VERSION ""

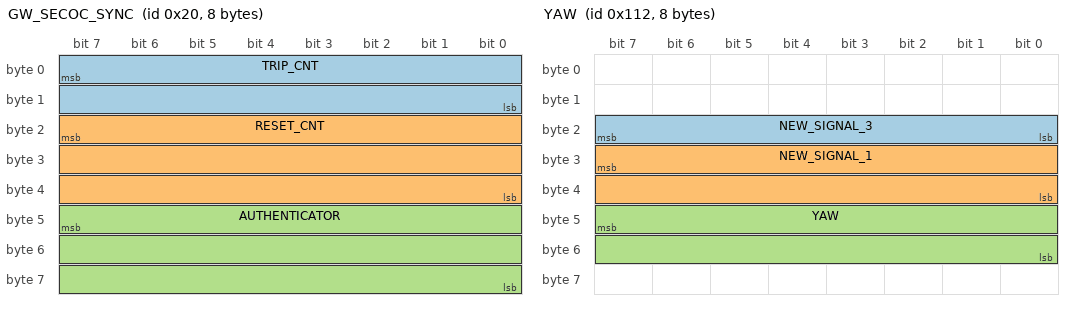
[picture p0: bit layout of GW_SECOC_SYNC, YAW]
BO_ 32 GW_SECOC_SYNC: 8 XXX
 SG_ TRIP_CNT : 7|16@0+ (1,0) [0|65535] "" XXX
 SG_ RESET_CNT : 23|24@0+ (1,0) [0|16777215] "" XXX
 SG_ AUTHENTICATOR : 47|24@0+ (1,0) [0|16777215] "" XXX

BO_ 89 NEW_MSG_59: 8 XXX
 SG_ NEW_SIGNAL_1 : 7|8@0+ (1,0) [0|255] "" XXX
 SG_ NEW_SIGNAL_2 : 11|4@0+ (1,0) [0|15] "" XXX

BO_ 237 NEW_MSG_ED: 8 XXX
 SG_ SECOC_CHECKSUM : 7|8@0+ (1,0) [0|255] "" XXX
 SG_ SECOC_COUNTER : 11|4@0+ (1,0) [0|15] "" XXX

BO_ 258 NEW_MSG_102: 8 XXX
 SG_ NEW_SIGNAL_1 : 23|16@0+ (1,0) [0|65535] "" XXX
 SG_ NEW_SIGNAL_2 : 39|16@0+ (1,0) [0|65535] "" XXX
 SG_ NEW_SIGNAL_3 : 55|16@0+ (1,0) [0|65535] "" XXX

BO_ 274 YAW: 8 XXX
 SG_ NEW_SIGNAL_3 : 23|8@0+ (1,0) [0|255] "" XXX
 SG_ NEW_SIGNAL_1 : 31|16@0+ (1,0) [0|255] "" XXX
 SG_ YAW : 47|16@0+ (1,0) [0|4095] "" XXX

BO_ 275 NEW_MSG_113: 8 XXX
 SG_ NEW_SIGNAL_2 : 16|1@0+ (1,0) [0|255] "" XXX
 SG_ NEW_SIGNAL_1 : 27|12@0+ (1,0) [0|255] "" XXX

BO_ 276 NEW_MSG_114: 8 XXX
 SG_ SECOC_CHECKSUM : 7|8@0+ (1,0) [0|255] "" XXX
 SG_ SECOC_COUNTER : 11|4@0+ (1,0) [0|15] "" XXX
 SG_ NEW_SIGNAL_1 : 23|24@0+ (1,0) [0|16777215] "" XXX

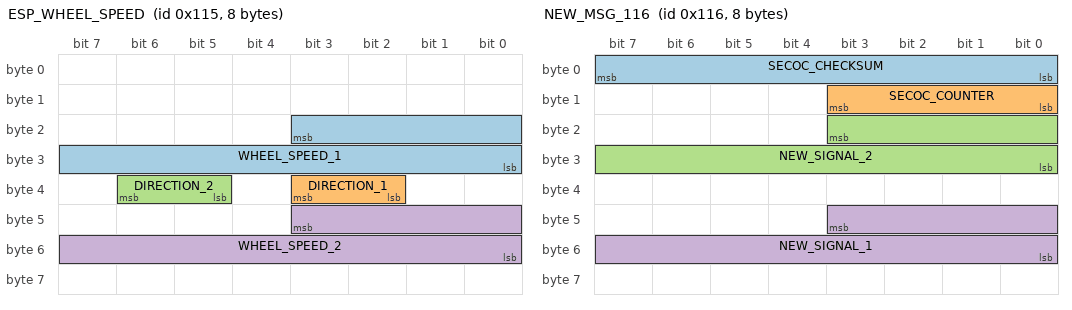
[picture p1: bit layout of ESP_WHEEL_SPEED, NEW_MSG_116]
BO_ 277 ESP_WHEEL_SPEED: 8 XXX
 SG_ WHEEL_SPEED_1 : 19|12@0+ (0.075,0) [0|255] "km/h" XXX
 SG_ DIRECTION_1 : 35|2@0+ (1,0) [0|3] "" XXX
 SG_ DIRECTION_2 : 38|2@0+ (1,0) [0|3] "" XXX
 SG_ WHEEL_SPEED_2 : 43|12@0+ (0.075,0) [0|255] "km/h" XXX

BO_ 278 NEW_MSG_116: 8 XXX
 SG_ SECOC_CHECKSUM : 7|8@0+ (1,0) [0|255] "" XXX
 SG_ SECOC_COUNTER : 11|4@0+ (1,0) [0|15] "" XXX
 SG_ NEW_SIGNAL_2 : 19|12@0+ (1,0) [0|4095] "" XXX
 SG_ NEW_SIGNAL_1 : 43|12@0+ (1,0) [0|4095] "" XXX

BO_ 280 NEW_MSG_118: 8 XXX
 SG_ NEW_SIGNAL_2 : 23|8@0+ (1,0) [0|255] "" XXX
 SG_ NEW_SIGNAL_1 : 63|8@0+ (1,0) [0|255] "" XXX

BO_ 281 NEW_MSG_119: 8 XXX
 SG_ NEW_SIGNAL_1 : 23|8@0+ (1,0) [0|255] "" XXX

BO_ 288 BRAKE_PEDAL: 8 XXX
 SG_ BRAKE_PEDAL_POS : 22|11@0+ (1,0) [0|127] "" XXX
 SG_ BRAKE_PEDAL_POS_INV : 54|15@0+ (1,0) [0|127] "" XXX

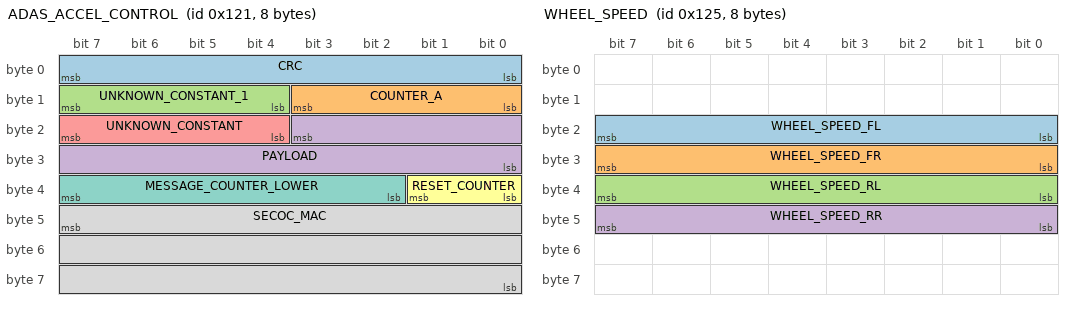
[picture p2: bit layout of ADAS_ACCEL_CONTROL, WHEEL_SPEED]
BO_ 289 ADAS_ACCEL_CONTROL: 8 XXX
 SG_ CRC : 7|8@0+ (1,0) [0|255] "" XXX
 SG_ COUNTER_A : 11|4@0+ (1,0) [0|255] "" XXX
 SG_ UNKNOWN_CONSTANT_1 : 15|4@0+ (1,0) [0|15] "" XXX
 SG_ PAYLOAD : 19|12@0+ (1,0) [0|4095] "" XXX
 SG_ UNKNOWN_CONSTANT : 23|4@0+ (1,0) [0|15] "" XXX
 SG_ RESET_COUNTER : 33|2@0+ (1,0) [0|3] "" XXX
 SG_ MESSAGE_COUNTER_LOWER : 39|6@0+ (1,0) [0|63] "" XXX
 SG_ SECOC_MAC : 47|24@0+ (1,0) [0|16777215] "" XXX

BO_ 293 WHEEL_SPEED: 8 XXX
 SG_ WHEEL_SPEED_FL : 23|8@0+ (1,0) [0|255] "" XXX
 SG_ WHEEL_SPEED_FR : 31|8@0+ (1,0) [0|255] "" XXX
 SG_ WHEEL_SPEED_RL : 39|8@0+ (1,0) [0|255] "" XXX
 SG_ WHEEL_SPEED_RR : 47|8@0+ (1,0) [0|255] "" XXX

BO_ 298 NEW_MSG_12A: 8 XXX
 SG_ NEW_SIGNAL_1 : 39|12@0+ (1,0) [0|4095] "" XXX
 SG_ NEW_SIGNAL_2 : 55|12@0+ (1,0) [0|4095] "" XXX

BO_ 336 NEW_MSG_150: 8 XXX
 SG_ NEW_SIGNAL_2 : 39|16@0+ (1,0) [0|65535] "" XXX

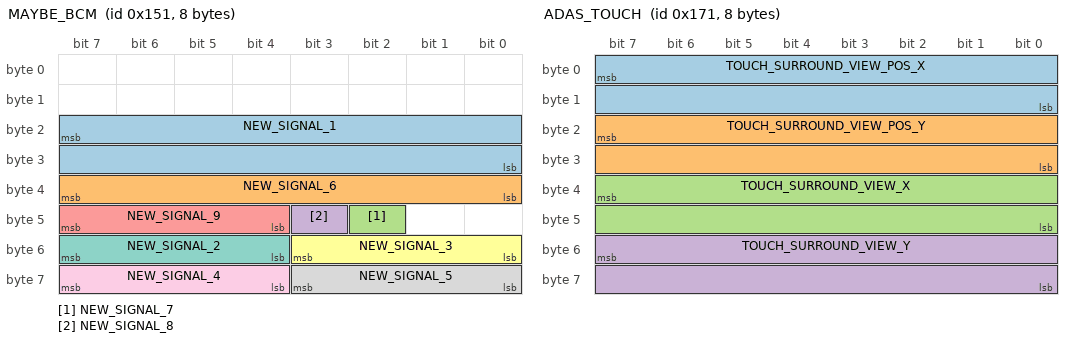
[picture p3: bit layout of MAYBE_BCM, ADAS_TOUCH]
BO_ 337 MAYBE_BCM: 8 XXX
 SG_ NEW_SIGNAL_1 : 23|16@0+ (1,0) [0|127] "" XXX
 SG_ NEW_SIGNAL_6 : 39|8@0+ (1,0) [0|255] "" XXX
 SG_ NEW_SIGNAL_7 : 42|1@0+ (1,0) [0|1] "" XXX
 SG_ NEW_SIGNAL_8 : 43|1@0+ (1,0) [0|1] "" XXX
 SG_ NEW_SIGNAL_9 : 47|4@0+ (1,0) [0|15] "" XXX
 SG_ NEW_SIGNAL_3 : 51|4@0+ (1,0) [0|15] "" XXX
 SG_ NEW_SIGNAL_2 : 55|4@0+ (1,0) [0|15] "" XXX
 SG_ NEW_SIGNAL_5 : 59|4@0+ (1,0) [0|15] "" XXX
 SG_ NEW_SIGNAL_4 : 63|4@0+ (1,0) [0|15] "" XXX

BO_ 345 NEW_MSG_159: 8 XXX
 SG_ NEW_SIGNAL_3 : 19|4@0+ (1,0) [0|15] "" XXX
 SG_ NEW_SIGNAL_1 : 23|4@0+ (1,0) [0|255] "" XXX
 SG_ NEW_SIGNAL_2 : 24|4@1+ (1,0) [0|15] "" XXX

BO_ 368 NEW_MSG_170: 8 XXX
 SG_ NEW_SIGNAL_3 : 23|8@0+ (1,0) [0|255] "" XXX
 SG_ NEW_SIGNAL_4 : 31|4@0+ (1,0) [0|15] "" XXX
 SG_ NEW_SIGNAL_1 : 39|12@0+ (1,0) [0|4095] "" XXX

BO_ 369 ADAS_TOUCH: 8 XXX
 SG_ TOUCH_SURROUND_VIEW_POS_X : 7|16@0+ (1,0) [0|65535] "" XXX
 SG_ TOUCH_SURROUND_VIEW_POS_Y : 23|16@0+ (1,0) [0|65535] "" XXX
 SG_ TOUCH_SURROUND_VIEW_X : 39|16@0+ (1,0) [0|65535] "" XXX
 SG_ TOUCH_SURROUND_VIEW_Y : 55|16@0+ (1,0) [0|65535] "" XXX

BO_ 372 NEW_MSG_174: 8 XXX
 SG_ NEW_SIGNAL_2 : 23|8@0+ (1,0) [0|255] "" XXX
 SG_ NEW_SIGNAL_1 : 31|8@0+ (1,0) [0|255] "" XXX
 SG_ NEW_SIGNAL_4 : 39|16@0+ (1,0) [0|255] "" XXX
 SG_ NEW_SIGNAL_5 : 55|8@0+ (1,0) [0|255] "" XXX
 SG_ NEW_SIGNAL_6 : 63|8@0+ (1,0) [0|255] "" XXX

BO_ 373 NEW_MSG_175: 8 XXX
 SG_ NEW_SIGNAL_1 : 23|16@0+ (1,0) [0|65535] "" XXX
 SG_ NEW_SIGNAL_2 : 39|16@0+ (1,0) [0|65535] "" XXX
 SG_ NEW_SIGNAL_3 : 55|16@0+ (1,0) [0|65535] "" XXX

BO_ 375 NEW_MSG_177: 8 XXX
 SG_ NEW_SIGNAL_2 : 39|16@0+ (1,0) [0|65535] "" XXX
 SG_ NEW_SIGNAL_1 : 55|16@0+ (1,0) [0|32767] "" XXX

BO_ 376 NEW_MSG_178: 8 XXX
 SG_ NEW_SIGNAL_1 : 23|16@0+ (1,0) [0|65535] "" XXX
 SG_ NEW_SIGNAL_2 : 47|8@0+ (1,0) [0|65535] "" XXX
 SG_ NEW_SIGNAL_3 : 55|16@0+ (1,0) [0|65535] "" XXX

BO_ 377 NEW_MSG_179: 8 XXX
 SG_ MAYBE_YAW_RELATED : 23|16@0+ (1,0) [0|255] "" XXX
 SG_ NEW_SIGNAL_2 : 39|16@0+ (1,0) [0|65535] "" XXX

BO_ 440 NEW_MSG_1B8: 8 XXX
 SG_ NEW_SIGNAL_1 : 51|12@0+ (1,0) [0|255] "" XXX

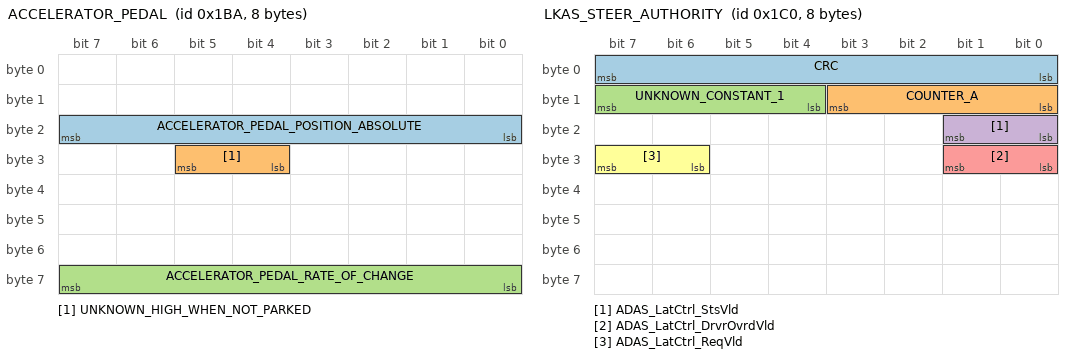
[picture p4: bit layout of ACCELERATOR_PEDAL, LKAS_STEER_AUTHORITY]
BO_ 442 ACCELERATOR_PEDAL: 8 XXX
 SG_ ACCELERATOR_PEDAL_POSITION_ABSOLUTE : 23|8@0+ (1,0) [0|255] "" XXX
 SG_ UNKNOWN_HIGH_WHEN_NOT_PARKED : 29|2@0+ (1,0) [0|3] "" XXX
 SG_ ACCELERATOR_PEDAL_RATE_OF_CHANGE : 63|8@0+ (1,0) [0|255] "" XXX

BO_ 448 LKAS_STEER_AUTHORITY: 8 XXX
 SG_ CRC : 7|8@0+ (1,0) [0|255] "" XXX
 SG_ COUNTER_A : 11|4@0+ (1,0) [0|15] "" XXX
 SG_ UNKNOWN_CONSTANT_1 : 15|4@0+ (1,0) [0|15] "" XXX
 SG_ ADAS_LatCtrl_StsVld : 17|2@0+ (1,0) [0|3] "" XXX
 SG_ ADAS_LatCtrl_DrvrOvrdVld : 25|2@0+ (1,0) [0|3] "" XXX
 SG_ ADAS_LatCtrl_ReqVld : 31|2@0+ (1,0) [0|3] "" XXX

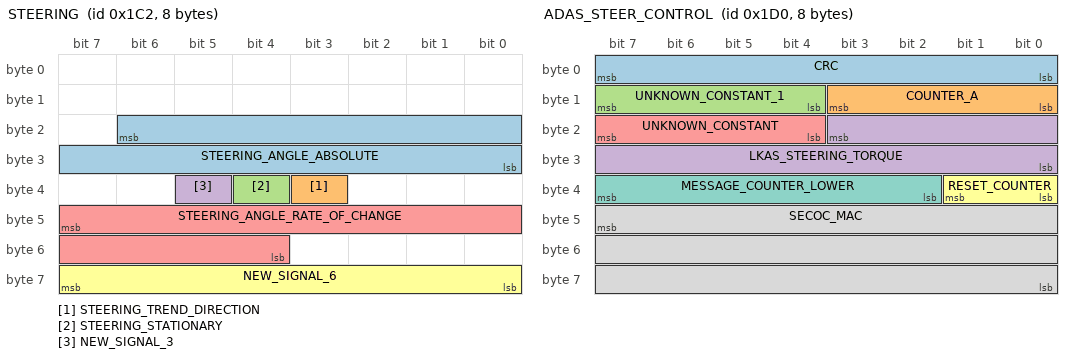
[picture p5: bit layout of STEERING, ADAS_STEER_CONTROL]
BO_ 450 STEERING: 8 XXX
 SG_ STEERING_ANGLE_ABSOLUTE : 22|15@0+ (0.0643,-800) [0|255] "" XXX
 SG_ STEERING_TREND_DIRECTION : 35|1@0+ (1,0) [0|1] "" XXX
 SG_ STEERING_STATIONARY : 36|1@0+ (1,0) [0|1] "" XXX
 SG_ NEW_SIGNAL_3 : 37|1@0+ (1,0) [0|255] "" XXX
 SG_ STEERING_ANGLE_RATE_OF_CHANGE : 47|12@0+ (1,0) [0|255] "" XXX
 SG_ NEW_SIGNAL_6 : 63|8@0+ (1,0) [0|255] "" XXX

BO_ 452 STEERING_WHEEL1: 8 XXX
 SG_ STEERING_WHEEL_INPUT_TORQUE : 23|12@0- (1,0) [-2048|2047] "" XXX
 SG_ STEERING_WHEEL_POS_ABSOLUTE : 55|16@0+ (1,-12500) [0|255] "" XXX

BO_ 464 ADAS_STEER_CONTROL: 8 XXX
 SG_ CRC : 7|8@0+ (1,0) [0|255] "" XXX
 SG_ COUNTER_A : 11|4@0+ (1,0) [0|15] "" XXX
 SG_ UNKNOWN_CONSTANT_1 : 15|4@0+ (1,0) [0|15] "" XXX
 SG_ LKAS_STEERING_TORQUE : 19|12@0+ (1,-192) [-192|192] "" XXX
 SG_ UNKNOWN_CONSTANT : 23|4@0+ (1,0) [0|15] "" XXX
 SG_ RESET_COUNTER : 33|2@0+ (1,0) [0|3] "" XXX
 SG_ MESSAGE_COUNTER_LOWER : 39|6@0+ (1,0) [0|3] "" XXX
 SG_ SECOC_MAC : 47|24@0+ (1,0) [0|16777215] "" XXX

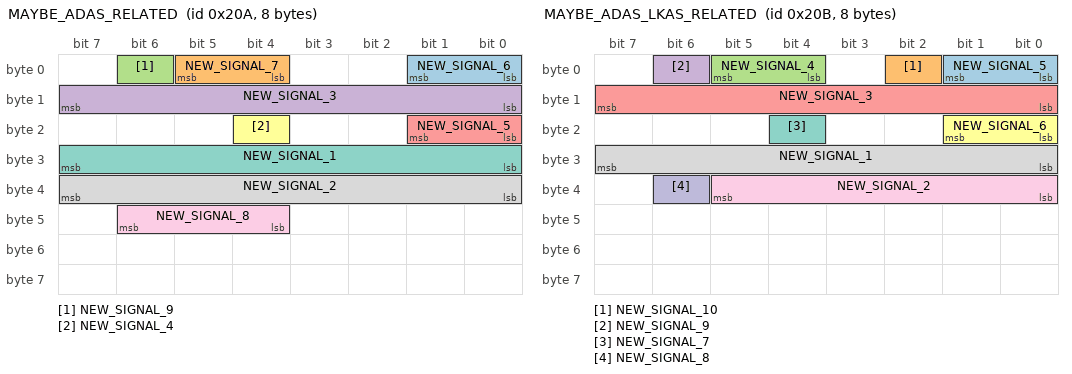
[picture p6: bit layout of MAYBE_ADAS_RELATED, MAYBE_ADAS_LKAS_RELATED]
BO_ 522 MAYBE_ADAS_RELATED: 8 XXX
 SG_ NEW_SIGNAL_6 : 1|2@0+ (1,0) [0|3] "" XXX
 SG_ NEW_SIGNAL_7 : 5|2@0+ (1,0) [0|7] "" XXX
 SG_ NEW_SIGNAL_9 : 6|1@0+ (1,0) [0|1] "" XXX
 SG_ NEW_SIGNAL_3 : 15|8@0+ (1,0) [0|255] "" XXX
 SG_ NEW_SIGNAL_5 : 17|2@0+ (1,0) [0|3] "" XXX
 SG_ NEW_SIGNAL_4 : 20|1@0+ (1,0) [0|1] "" XXX
 SG_ NEW_SIGNAL_1 : 31|8@0+ (1,0) [0|255] "" XXX
 SG_ NEW_SIGNAL_2 : 39|8@0+ (1,0) [0|255] "" XXX
 SG_ NEW_SIGNAL_8 : 46|3@0+ (1,0) [0|7] "" XXX

BO_ 523 MAYBE_ADAS_LKAS_RELATED: 8 XXX
 SG_ NEW_SIGNAL_5 : 1|2@0+ (1,0) [0|1] "" XXX
 SG_ NEW_SIGNAL_10 : 2|1@0+ (1,0) [0|1] "" XXX
 SG_ NEW_SIGNAL_4 : 5|2@0+ (1,0) [0|1] "" XXX
 SG_ NEW_SIGNAL_9 : 6|1@0+ (1,0) [0|1] "" XXX
 SG_ NEW_SIGNAL_3 : 15|8@0+ (1,0) [0|255] "" XXX
 SG_ NEW_SIGNAL_6 : 17|2@0+ (1,0) [0|3] "" XXX
 SG_ NEW_SIGNAL_7 : 20|1@0+ (1,0) [0|1] "" XXX
 SG_ NEW_SIGNAL_1 : 31|8@0+ (1,0) [0|255] "" XXX
 SG_ NEW_SIGNAL_2 : 37|6@0+ (1,0) [0|255] "" XXX
 SG_ NEW_SIGNAL_8 : 38|1@0+ (1,0) [0|1] "" XXX

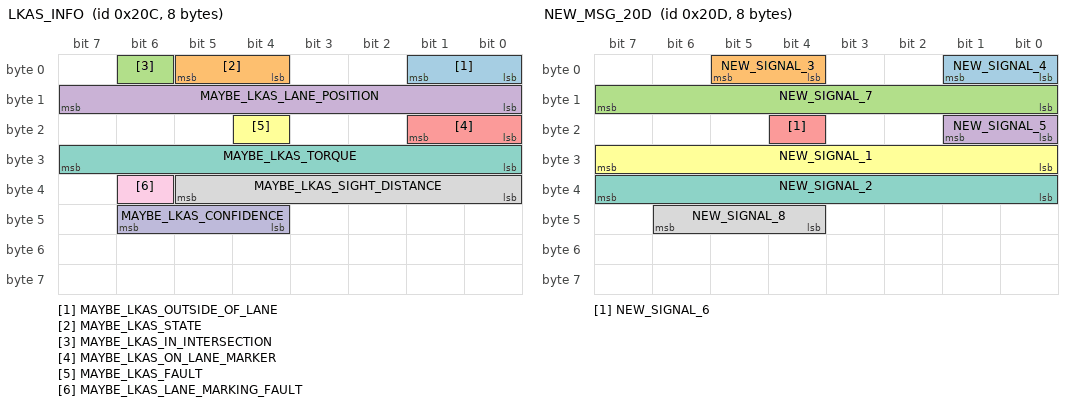
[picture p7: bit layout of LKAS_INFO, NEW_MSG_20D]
BO_ 524 LKAS_INFO: 8 XXX
 SG_ MAYBE_LKAS_OUTSIDE_OF_LANE : 1|2@0+ (1,0) [0|3] "" XXX
 SG_ MAYBE_LKAS_STATE : 5|2@0+ (1,0) [0|7] "" XXX
 SG_ MAYBE_LKAS_IN_INTERSECTION : 6|1@0+ (1,0) [0|1] "" XXX
 SG_ MAYBE_LKAS_LANE_POSITION : 15|8@0+ (1,0) [0|255] "" XXX
 SG_ MAYBE_LKAS_ON_LANE_MARKER : 17|2@0+ (1,0) [0|3] "" XXX
 SG_ MAYBE_LKAS_FAULT : 20|1@0+ (1,0) [0|1] "" XXX
 SG_ MAYBE_LKAS_TORQUE : 31|8@0+ (1,0) [0|255] "" XXX
 SG_ MAYBE_LKAS_SIGHT_DISTANCE : 37|6@0+ (1,0) [0|255] "" XXX
 SG_ MAYBE_LKAS_LANE_MARKING_FAULT : 38|1@0+ (1,0) [0|1] "" XXX
 SG_ MAYBE_LKAS_CONFIDENCE : 46|3@0+ (1,0) [0|7] "" XXX

BO_ 525 NEW_MSG_20D: 8 XXX
 SG_ NEW_SIGNAL_4 : 1|2@0+ (1,0) [0|3] "" XXX
 SG_ NEW_SIGNAL_3 : 5|2@0+ (1,0) [0|3] "" XXX
 SG_ NEW_SIGNAL_7 : 15|8@0+ (1,0) [0|255] "" XXX
 SG_ NEW_SIGNAL_5 : 17|2@0+ (1,0) [0|3] "" XXX
 SG_ NEW_SIGNAL_6 : 20|1@0+ (1,0) [0|1] "" XXX
 SG_ NEW_SIGNAL_1 : 31|8@0+ (1,0) [0|127] "" XXX
 SG_ NEW_SIGNAL_2 : 39|8@0+ (1,0) [0|255] "" XXX
 SG_ NEW_SIGNAL_8 : 46|3@0+ (1,0) [0|7] "" XXX

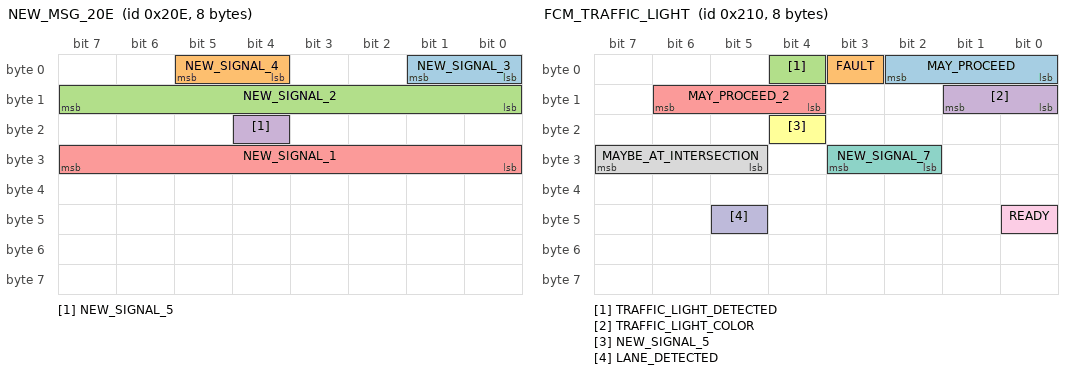
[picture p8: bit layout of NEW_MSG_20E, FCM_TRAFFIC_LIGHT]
BO_ 526 NEW_MSG_20E: 8 XXX
 SG_ NEW_SIGNAL_3 : 1|2@0+ (1,0) [0|3] "" XXX
 SG_ NEW_SIGNAL_4 : 5|2@0+ (1,0) [0|3] "" XXX
 SG_ NEW_SIGNAL_2 : 15|8@0+ (1,0) [0|255] "" XXX
 SG_ NEW_SIGNAL_5 : 20|1@0+ (1,0) [0|1] "" XXX
 SG_ NEW_SIGNAL_1 : 31|8@0+ (1,0) [0|255] "" XXX

BO_ 527 NEW_MSG_20F: 8 XXX
 SG_ NEW_SIGNAL_2 : 2|3@0+ (1,0) [0|7] "" XXX
 SG_ NEW_SIGNAL_1 : 5|3@0+ (1,0) [0|7] "" XXX

BO_ 528 FCM_TRAFFIC_LIGHT: 8 XXX
 SG_ MAY_PROCEED : 2|3@0+ (1,0) [0|7] "" XXX
 SG_ FAULT : 3|1@0+ (1,0) [0|1] "" XXX
 SG_ TRAFFIC_LIGHT_DETECTED : 4|1@0+ (1,0) [0|1] "" XXX
 SG_ TRAFFIC_LIGHT_COLOR : 9|2@0+ (1,0) [0|3] "" XXX
 SG_ MAY_PROCEED_2 : 14|3@0+ (1,0) [0|7] "" XXX
 SG_ NEW_SIGNAL_5 : 20|1@0+ (1,0) [0|1] "" XXX
 SG_ NEW_SIGNAL_7 : 27|2@0+ (1,0) [0|3] "" XXX
 SG_ MAYBE_AT_INTERSECTION : 31|3@0+ (1,0) [0|7] "" XXX
 SG_ READY : 40|1@0+ (1,0) [0|1] "" XXX
 SG_ LANE_DETECTED : 45|1@0+ (1,0) [0|1] "" XXX

BO_ 532 BCM: 16 XXX
 SG_ NEW_SIGNAL_6 : 12|1@0+ (1,0) [0|1] "" XXX
 SG_ BRAKE_PRESSED_1 : 14|1@0+ (1,0) [0|1] "" XXX
 SG_ DRIVE_MODE_1 : 18|3@0+ (1,0) [0|7] "" XXX
 SG_ DRIVE_MODE_2 : 26|3@0+ (1,0) [0|7] "" XXX
 SG_ NEW_SIGNAL_4 : 43|4@0+ (1,0) [0|7] "" XXX
 SG_ ACCELERATOR_PEDAL_POSITION_ABSOLUTE : 55|8@0+ (1,0) [0|255] "" XXX
 SG_ BRAKE_PRESSED_2 : 56|1@0+ (1,0) [0|1] "" XXX
 SG_ NEW_SIGNAL_1 : 60|2@0+ (1,0) [0|3] "" XXX

BO_ 588 NEW_MSG_24C: 32 XXX
 SG_ NEW_SIGNAL_7 : 23|8@0+ (1,0) [0|255] "" XXX
 SG_ NEW_SIGNAL_4 : 31|16@0+ (1,0) [0|65535] "" XXX
 SG_ NEW_SIGNAL_5 : 43|12@0+ (1,0) [0|255] "" XXX
 SG_ NEW_SIGNAL_3 : 59|12@0+ (1,0) [0|255] "" XXX
 SG_ NEW_SIGNAL_2 : 79|8@0+ (1,0) [0|255] "" XXX
 SG_ NEW_SIGNAL_1 : 111|8@0+ (1,0) [0|255] "" XXX
 SG_ NEW_SIGNAL_6 : 143|19@0+ (1,0) [0|524287] "" XXX
 SG_ NEW_SIGNAL_8 : 156|3@0+ (1,0) [0|7] "" XXX
 SG_ NEW_SIGNAL_9 : 172|5@0+ (1,0) [0|31] "" XXX
 SG_ NEW_SIGNAL_10 : 191|8@0+ (1,0) [0|255] "" XXX
 SG_ NEW_SIGNAL_11 : 218|3@0+ (1,0) [0|7] "" XXX

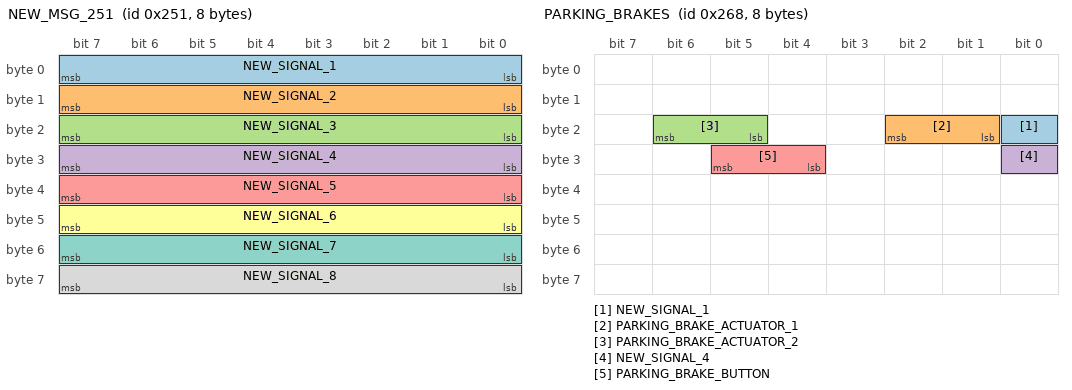
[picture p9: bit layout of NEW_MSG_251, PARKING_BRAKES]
BO_ 593 NEW_MSG_251: 8 XXX
 SG_ NEW_SIGNAL_1 : 7|8@0+ (1,0) [0|255] "" XXX
 SG_ NEW_SIGNAL_2 : 8|8@1+ (1,0) [0|255] "" XXX
 SG_ NEW_SIGNAL_3 : 23|8@0+ (1,0) [0|255] "" XXX
 SG_ NEW_SIGNAL_4 : 31|8@0+ (1,0) [0|255] "" XXX
 SG_ NEW_SIGNAL_5 : 39|8@0+ (1,0) [0|255] "" XXX
 SG_ NEW_SIGNAL_6 : 47|8@0+ (1,0) [0|255] "" XXX
 SG_ NEW_SIGNAL_7 : 55|8@0+ (1,0) [0|255] "" XXX
 SG_ NEW_SIGNAL_8 : 63|8@0+ (1,0) [0|255] "" XXX

BO_ 616 PARKING_BRAKES: 8 XXX
 SG_ NEW_SIGNAL_1 : 16|1@0+ (1,0) [0|1] "" XXX
 SG_ PARKING_BRAKE_ACTUATOR_1 : 18|2@0+ (1,0) [0|3] "" XXX
 SG_ PARKING_BRAKE_ACTUATOR_2 : 22|2@0+ (1,0) [0|3] "" XXX
 SG_ NEW_SIGNAL_4 : 24|1@0+ (1,0) [0|1] "" XXX
 SG_ PARKING_BRAKE_BUTTON : 29|2@0+ (1,0) [0|3] "" XXX

BO_ 678 NEW_MSG_2A6: 8 XXX
 SG_ NEW_SIGNAL_1 : 11|4@0+ (1,0) [0|15] "" XXX
 SG_ NEW_SIGNAL_2 : 18|3@0+ (1,0) [0|7] "" XXX

BO_ 767 NEW_MSG_2FF: 8 XXX
 SG_ NEW_SIGNAL_1 : 23|16@0+ (1,0) [0|255] "" XXX
 SG_ NEW_SIGNAL_2 : 39|16@0+ (1,0) [0|65535] "" XXX

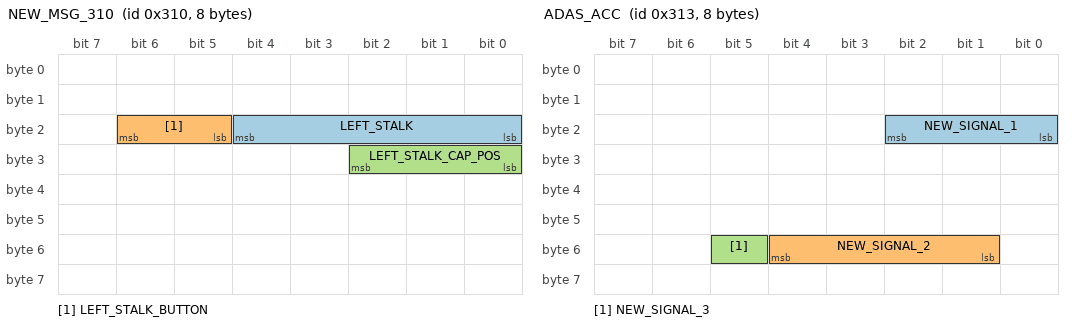
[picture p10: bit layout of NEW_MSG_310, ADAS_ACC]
BO_ 784 NEW_MSG_310: 8 XXX
 SG_ LEFT_STALK : 20|5@0+ (1,0) [0|31] "" XXX
 SG_ LEFT_STALK_BUTTON : 22|2@0+ (1,0) [0|1] "" XXX
 SG_ LEFT_STALK_CAP_POS : 26|3@0+ (1,0) [0|1] "" XXX

BO_ 785 NEW_MSG_311: 8 XXX
 SG_ NEW_SIGNAL_1 : 52|4@0+ (1,0) [0|15] "" XXX

BO_ 787 ADAS_ACC: 8 XXX
 SG_ NEW_SIGNAL_1 : 18|3@0+ (1,0) [0|7] "" XXX
 SG_ NEW_SIGNAL_2 : 52|4@0+ (1,0) [0|1] "" XXX
 SG_ NEW_SIGNAL_3 : 53|1@0+ (1,0) [0|1] "" XXX

BO_ 788 NEW_MSG_314: 8 XXX
 SG_ NEW_SIGNAL_2 : 23|8@0+ (1,0) [0|255] "" XXX
 SG_ NEW_SIGNAL_3 : 31|8@0+ (1,0) [0|255] "" XXX
 SG_ NEW_SIGNAL_4 : 39|8@0+ (1,0) [0|255] "" XXX
 SG_ NEW_SIGNAL_5 : 47|8@0+ (1,0) [0|255] "" XXX
 SG_ NEW_SIGNAL_1 : 55|8@0+ (1,0) [0|255] "" XXX
 SG_ NEW_SIGNAL_6 : 63|8@0+ (1,0) [0|255] "" XXX

BO_ 789 NEW_MSG_315: 8 XXX
 SG_ NEW_SIGNAL_1 : 43|1@0+ (1,0) [0|1] "" XXX

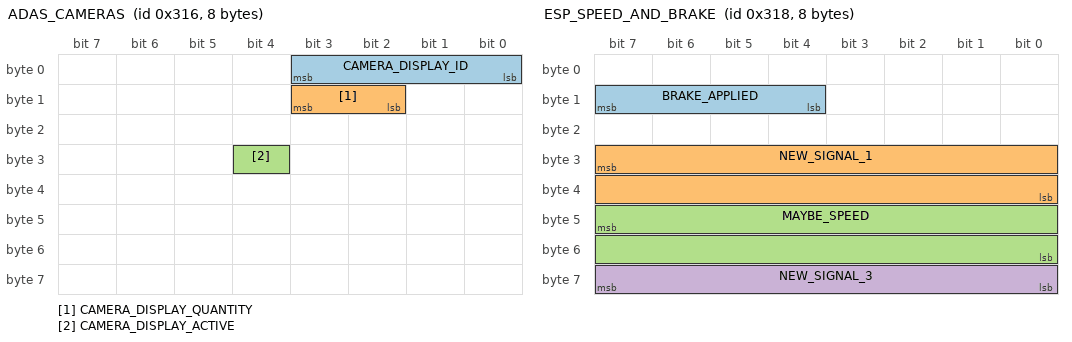
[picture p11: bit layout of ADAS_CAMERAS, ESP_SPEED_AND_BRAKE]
BO_ 790 ADAS_CAMERAS: 8 XXX
 SG_ CAMERA_DISPLAY_ID : 3|4@0+ (1,0) [0|15] "" XXX
 SG_ CAMERA_DISPLAY_QUANTITY : 11|2@0+ (1,0) [0|3] "" XXX
 SG_ CAMERA_DISPLAY_ACTIVE : 28|1@0+ (1,0) [0|1] "" XXX

BO_ 791 NEW_MSG_317: 8 XXX
 SG_ NEW_SIGNAL_1 : 23|8@0+ (1,0) [0|3] "" XXX
 SG_ NEW_SIGNAL_3 : 31|8@0+ (1,0) [0|255] "" XXX
 SG_ NEW_SIGNAL_4 : 39|8@0+ (1,0) [0|255] "" XXX
 SG_ NEW_SIGNAL_5 : 47|8@0+ (1,0) [0|255] "" XXX
 SG_ NEW_SIGNAL_2 : 55|8@0+ (1,0) [0|255] "" XXX

BO_ 792 ESP_SPEED_AND_BRAKE: 8 XXX
 SG_ BRAKE_APPLIED : 15|4@0+ (1,0) [0|15] "" XXX
 SG_ NEW_SIGNAL_1 : 31|16@0+ (1,0) [0|255] "" XXX
 SG_ MAYBE_SPEED : 47|16@0+ (1,0) [0|255] "" XXX
 SG_ NEW_SIGNAL_3 : 63|8@0+ (1,0) [0|255] "" XXX

BO_ 794 NEW_MSG_31A: 8 XXX
 SG_ NEW_SIGNAL_1 : 23|8@0+ (1,0) [0|255] "" XXX
 SG_ NEW_SIGNAL_2 : 63|8@0+ (1,0) [0|255] "" XXX

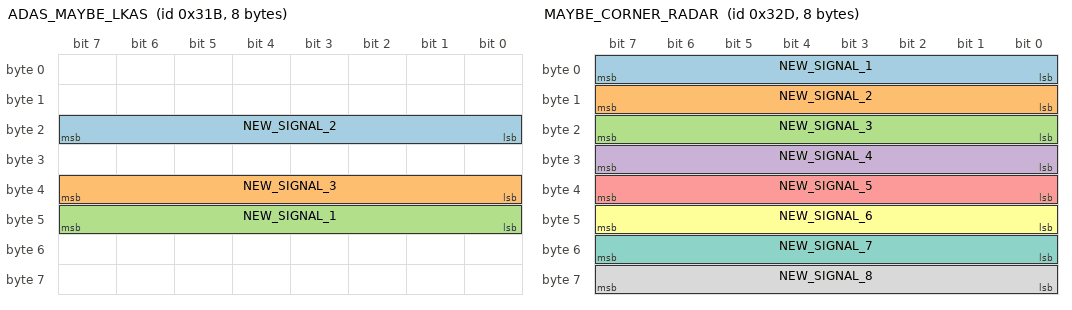
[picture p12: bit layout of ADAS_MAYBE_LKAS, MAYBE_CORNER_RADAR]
BO_ 795 ADAS_MAYBE_LKAS: 8 XXX
 SG_ NEW_SIGNAL_2 : 23|8@0+ (1,0) [0|255] "" XXX
 SG_ NEW_SIGNAL_3 : 39|8@0+ (1,0) [0|255] "" XXX
 SG_ NEW_SIGNAL_1 : 40|8@1+ (1,0) [0|255] "" XXX

BO_ 796 ADAS_ACC_HUD: 8 XXX

BO_ 801 NEW_MSG_321: 8 XXX
 SG_ NEW_SIGNAL_1 : 49|2@0+ (1,0) [0|3] "" XXX

BO_ 813 MAYBE_CORNER_RADAR: 8 XXX
 SG_ NEW_SIGNAL_1 : 7|8@0+ (1,0) [0|255] "" XXX
 SG_ NEW_SIGNAL_2 : 15|8@0+ (1,0) [0|255] "" XXX
 SG_ NEW_SIGNAL_3 : 23|8@0+ (1,0) [0|255] "" XXX
 SG_ NEW_SIGNAL_4 : 31|8@0+ (1,0) [0|255] "" XXX
 SG_ NEW_SIGNAL_5 : 39|8@0+ (1,0) [0|255] "" XXX
 SG_ NEW_SIGNAL_6 : 47|8@0+ (1,0) [0|255] "" XXX
 SG_ NEW_SIGNAL_7 : 55|8@0+ (1,0) [0|255] "" XXX
 SG_ NEW_SIGNAL_8 : 63|8@0+ (1,0) [0|255] "" XXX

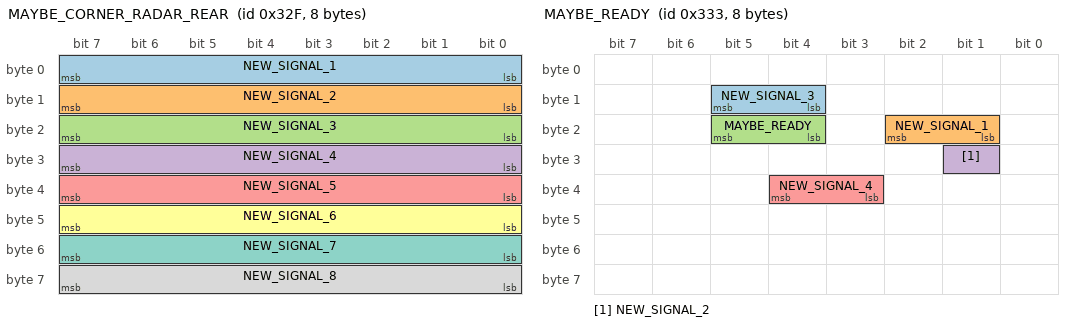
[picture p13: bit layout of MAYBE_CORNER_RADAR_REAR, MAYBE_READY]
BO_ 815 MAYBE_CORNER_RADAR_REAR: 8 XXX
 SG_ NEW_SIGNAL_1 : 7|8@0+ (1,0) [0|255] "" XXX
 SG_ NEW_SIGNAL_2 : 15|8@0+ (1,0) [0|255] "" XXX
 SG_ NEW_SIGNAL_3 : 23|8@0+ (1,0) [0|255] "" XXX
 SG_ NEW_SIGNAL_4 : 31|8@0+ (1,0) [0|255] "" XXX
 SG_ NEW_SIGNAL_5 : 39|8@0+ (1,0) [0|255] "" XXX
 SG_ NEW_SIGNAL_6 : 47|8@0+ (1,0) [0|255] "" XXX
 SG_ NEW_SIGNAL_7 : 55|8@0+ (1,0) [0|255] "" XXX
 SG_ NEW_SIGNAL_8 : 63|8@0+ (1,0) [0|255] "" XXX

BO_ 817 NEW_MSG_331: 16 XXX
 SG_ NEW_SIGNAL_1 : 20|2@0+ (1,0) [0|3] "" XXX

BO_ 819 MAYBE_READY: 8 XXX
 SG_ NEW_SIGNAL_3 : 13|2@0+ (1,0) [0|3] "" XXX
 SG_ NEW_SIGNAL_1 : 18|2@0+ (1,0) [0|3] "" XXX
 SG_ MAYBE_READY : 21|2@0+ (1,0) [0|3] "" XXX
 SG_ NEW_SIGNAL_2 : 25|1@0+ (1,0) [0|1] "" XXX
 SG_ NEW_SIGNAL_4 : 36|2@0+ (1,0) [0|3] "" XXX

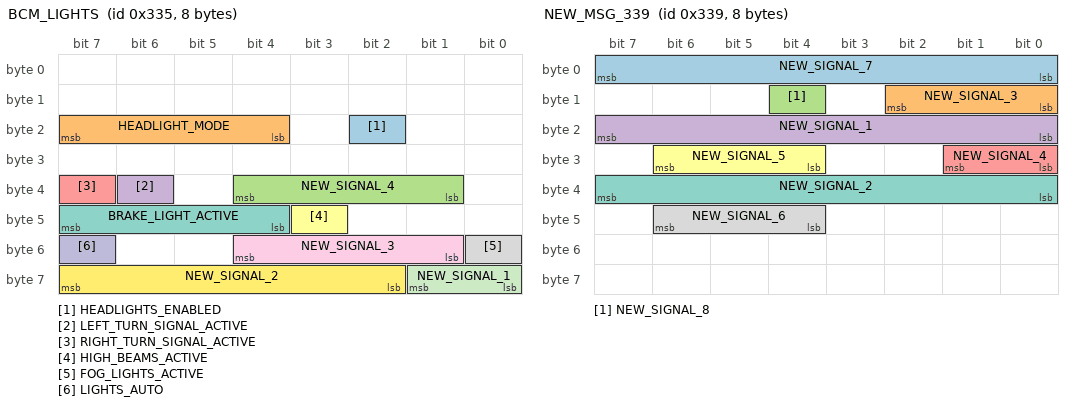
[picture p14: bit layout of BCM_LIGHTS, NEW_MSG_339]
BO_ 821 BCM_LIGHTS: 8 XXX
 SG_ HEADLIGHTS_ENABLED : 18|1@0+ (1,0) [0|1] "" XXX
 SG_ HEADLIGHT_MODE : 23|4@0+ (1,0) [0|255] "" XXX
 SG_ NEW_SIGNAL_4 : 36|4@0+ (1,0) [0|15] "" XXX
 SG_ LEFT_TURN_SIGNAL_ACTIVE : 38|1@0+ (1,0) [0|1] "" XXX
 SG_ RIGHT_TURN_SIGNAL_ACTIVE : 39|1@0+ (1,0) [0|1] "" XXX
 SG_ HIGH_BEAMS_ACTIVE : 43|1@0+ (1,0) [0|1] "" XXX
 SG_ BRAKE_LIGHT_ACTIVE : 47|4@0+ (1,0) [0|15] "" XXX
 SG_ FOG_LIGHTS_ACTIVE : 48|1@0+ (1,0) [0|255] "" XXX
 SG_ NEW_SIGNAL_3 : 52|4@0+ (1,0) [0|15] "" XXX
 SG_ LIGHTS_AUTO : 55|1@0+ (1,0) [0|127] "" XXX
 SG_ NEW_SIGNAL_1 : 57|2@0+ (1,0) [0|3] "" XXX
 SG_ NEW_SIGNAL_2 : 63|6@0+ (1,0) [0|63] "" XXX

BO_ 825 NEW_MSG_339: 8 XXX
 SG_ NEW_SIGNAL_7 : 7|8@0+ (1,0) [0|255] "" XXX
 SG_ NEW_SIGNAL_3 : 10|3@0+ (1,0) [0|7] "" XXX
 SG_ NEW_SIGNAL_8 : 12|1@0+ (1,0) [0|1] "" XXX
 SG_ NEW_SIGNAL_1 : 23|8@0+ (1,0) [0|255] "" XXX
 SG_ NEW_SIGNAL_4 : 25|2@0+ (1,0) [0|3] "" XXX
 SG_ NEW_SIGNAL_5 : 30|3@0+ (1,0) [0|7] "" XXX
 SG_ NEW_SIGNAL_2 : 39|8@0+ (1,0) [0|255] "" XXX
 SG_ NEW_SIGNAL_6 : 46|3@0+ (1,0) [0|7] "" XXX

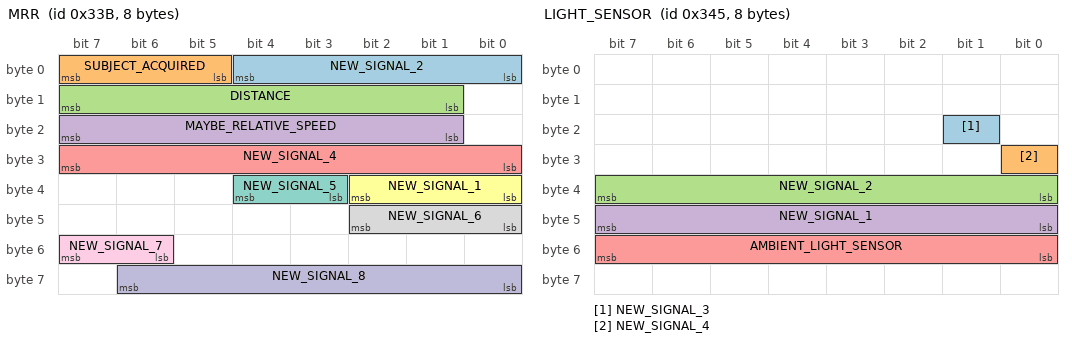
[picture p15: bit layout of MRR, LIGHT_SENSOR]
BO_ 827 MRR: 8 XXX
 SG_ NEW_SIGNAL_2 : 4|5@0+ (1,0) [0|31] "" XXX
 SG_ SUBJECT_ACQUIRED : 7|3@0+ (1,0) [0|1] "" XXX
 SG_ DISTANCE : 15|7@0+ (1,0) [0|255] "" XXX
 SG_ MAYBE_RELATIVE_SPEED : 23|7@0+ (1,0) [0|255] "" XXX
 SG_ NEW_SIGNAL_4 : 31|8@0+ (1,0) [0|255] "" XXX
 SG_ NEW_SIGNAL_1 : 34|3@0+ (1,0) [0|7] "" XXX
 SG_ NEW_SIGNAL_5 : 36|2@0+ (1,0) [0|255] "" XXX
 SG_ NEW_SIGNAL_6 : 42|3@0+ (1,0) [0|255] "" XXX
 SG_ NEW_SIGNAL_7 : 55|2@0+ (1,0) [0|255] "" XXX
 SG_ NEW_SIGNAL_8 : 62|7@0+ (1,0) [0|255] "" XXX

BO_ 835 BCM_DOORS: 8 XXX
 SG_ PARKED : 18|1@0+ (1,0) [0|1] "" XXX
 SG_ MAYBE_DOOR_OPEN : 22|2@0+ (1,0) [0|3] "" XXX

BO_ 837 LIGHT_SENSOR: 8 XXX
 SG_ NEW_SIGNAL_3 : 17|1@0+ (1,0) [0|1] "" XXX
 SG_ NEW_SIGNAL_4 : 24|1@0+ (1,0) [0|1] "" XXX
 SG_ NEW_SIGNAL_2 : 39|8@0+ (1,0) [0|255] "" XXX
 SG_ NEW_SIGNAL_1 : 47|8@0+ (1,0) [0|255] "" XXX
 SG_ AMBIENT_LIGHT_SENSOR : 55|8@0+ (1,0) [0|15] "" XXX

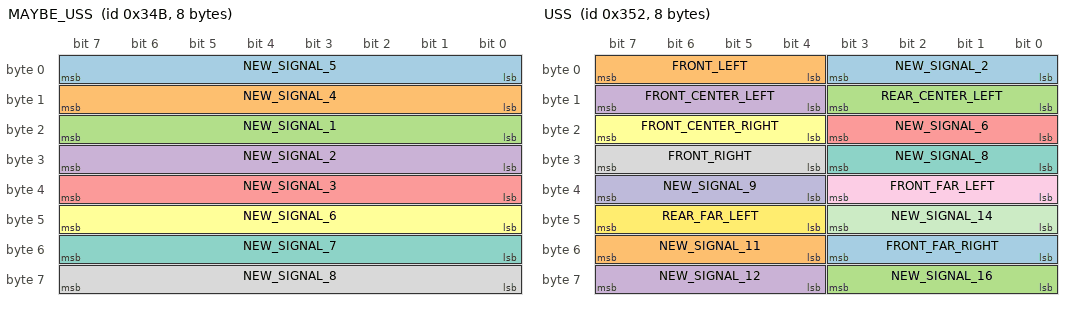
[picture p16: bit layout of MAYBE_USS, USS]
BO_ 843 MAYBE_USS: 8 XXX
 SG_ NEW_SIGNAL_5 : 7|8@0+ (1,0) [0|255] "" XXX
 SG_ NEW_SIGNAL_4 : 15|8@0+ (1,0) [0|255] "" XXX
 SG_ NEW_SIGNAL_1 : 23|8@0+ (1,0) [0|255] "" XXX
 SG_ NEW_SIGNAL_2 : 31|8@0+ (1,0) [0|255] "" XXX
 SG_ NEW_SIGNAL_3 : 39|8@0+ (1,0) [0|255] "" XXX
 SG_ NEW_SIGNAL_6 : 47|8@0+ (1,0) [0|255] "" XXX
 SG_ NEW_SIGNAL_7 : 55|8@0+ (1,0) [0|255] "" XXX
 SG_ NEW_SIGNAL_8 : 63|8@0+ (1,0) [0|255] "" XXX

BO_ 845 NEW_MSG_34D: 8 XXX
 SG_ NEW_SIGNAL_2 : 23|8@0+ (1,0) [0|255] "" XXX

BO_ 849 NEW_MSG_351: 8 XXX
 SG_ NEW_SIGNAL_1 : 48|8@1+ (1,0) [0|255] "" XXX

BO_ 850 USS: 8 XXX
 SG_ NEW_SIGNAL_2 : 3|4@0+ (1,0) [0|15] "" XXX
 SG_ FRONT_LEFT : 7|4@0+ (1,0) [0|15] "" XXX
 SG_ REAR_CENTER_LEFT : 11|4@0+ (1,0) [0|15] "" XXX
 SG_ FRONT_CENTER_LEFT : 15|4@0+ (1,0) [0|15] "" XXX
 SG_ NEW_SIGNAL_6 : 19|4@0+ (1,0) [0|15] "" XXX
 SG_ FRONT_CENTER_RIGHT : 23|4@0+ (1,0) [0|15] "" XXX
 SG_ NEW_SIGNAL_8 : 27|4@0+ (1,0) [0|15] "" XXX
 SG_ FRONT_RIGHT : 31|4@0+ (1,0) [0|15] "" XXX
 SG_ FRONT_FAR_LEFT : 35|4@0+ (1,0) [0|15] "" XXX
 SG_ NEW_SIGNAL_9 : 39|4@0+ (1,0) [0|15] "" XXX
 SG_ NEW_SIGNAL_14 : 43|4@0+ (1,0) [0|15] "" XXX
 SG_ REAR_FAR_LEFT : 47|4@0+ (1,0) [0|15] "" XXX
 SG_ FRONT_FAR_RIGHT : 51|4@0+ (1,0) [0|15] "" XXX
 SG_ NEW_SIGNAL_11 : 55|4@0+ (1,0) [0|15] "" XXX
 SG_ NEW_SIGNAL_16 : 59|4@0+ (1,0) [0|15] "" XXX
 SG_ NEW_SIGNAL_12 : 63|4@0+ (1,0) [0|15] "" XXX

BO_ 851 UNKNOWN_CHANGES_WITH_DRIVE_MODE_1: 8 XXX
 SG_ NEW_SIGNAL_1 : 23|4@0+ (1,0) [0|15] "" XXX

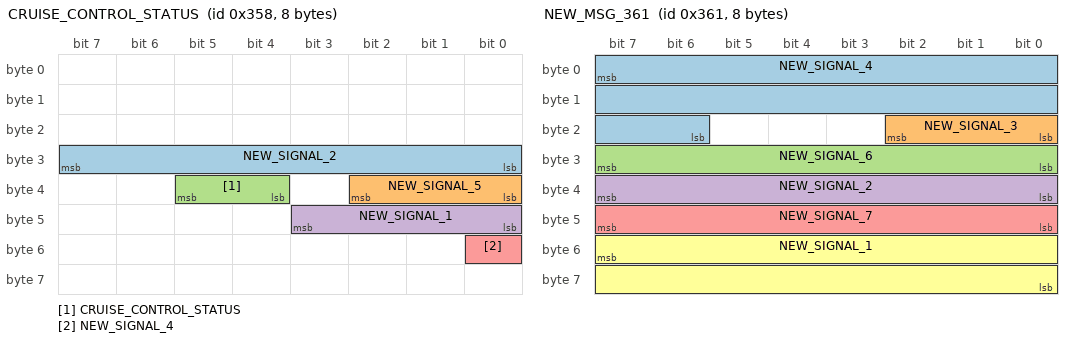
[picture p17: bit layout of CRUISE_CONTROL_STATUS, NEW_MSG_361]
BO_ 856 CRUISE_CONTROL_STATUS: 8 XXX
 SG_ NEW_SIGNAL_2 : 31|8@0+ (1,0) [0|255] "" XXX
 SG_ NEW_SIGNAL_5 : 34|3@0+ (1,0) [0|7] "" XXX
 SG_ CRUISE_CONTROL_STATUS : 37|2@0+ (1,0) [0|255] "" XXX
 SG_ NEW_SIGNAL_1 : 43|4@0+ (1,0) [0|15] "" XXX
 SG_ NEW_SIGNAL_4 : 48|1@0+ (1,0) [0|1] "" XXX

BO_ 859 NEW_MSG_35B: 8 XXX
 SG_ NEW_SIGNAL_2 : 16|1@0+ (1,0) [0|1] "" XXX
 SG_ NEW_SIGNAL_1 : 57|2@0+ (1,0) [0|3] "" XXX

BO_ 865 NEW_MSG_361: 8 XXX
 SG_ NEW_SIGNAL_4 : 7|18@0+ (1,0) [0|255] "" XXX
 SG_ NEW_SIGNAL_3 : 18|3@0+ (1,0) [0|7] "" XXX
 SG_ NEW_SIGNAL_6 : 31|8@0+ (1,0) [0|255] "" XXX
 SG_ NEW_SIGNAL_2 : 39|8@0+ (1,0) [0|255] "" XXX
 SG_ NEW_SIGNAL_7 : 47|8@0+ (1,0) [0|255] "" XXX
 SG_ NEW_SIGNAL_1 : 55|16@0+ (1,0) [0|255] "" XXX

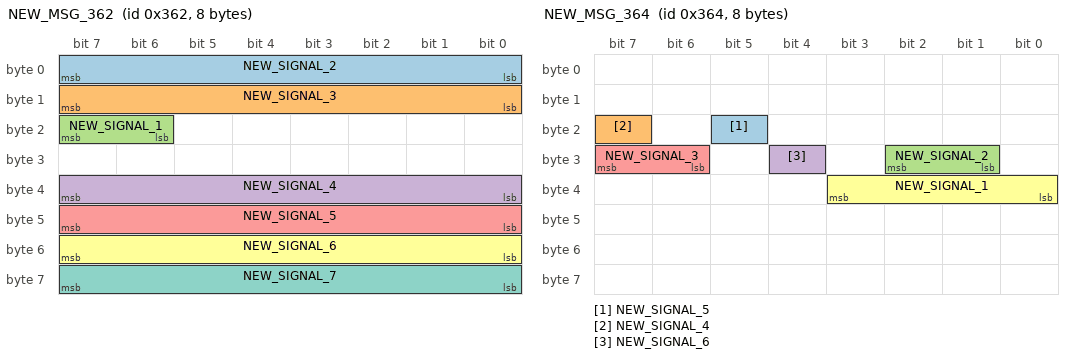
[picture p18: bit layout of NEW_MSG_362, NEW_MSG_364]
BO_ 866 NEW_MSG_362: 8 XXX
 SG_ NEW_SIGNAL_2 : 7|8@0+ (1,0) [0|255] "" XXX
 SG_ NEW_SIGNAL_3 : 15|8@0+ (1,0) [0|255] "" XXX
 SG_ NEW_SIGNAL_1 : 23|2@0+ (1,0) [0|3] "" XXX
 SG_ NEW_SIGNAL_4 : 39|8@0+ (1,0) [0|255] "" XXX
 SG_ NEW_SIGNAL_5 : 47|8@0+ (1,0) [0|255] "" XXX
 SG_ NEW_SIGNAL_6 : 55|8@0+ (1,0) [0|255] "" XXX
 SG_ NEW_SIGNAL_7 : 63|8@0+ (1,0) [0|255] "" XXX

BO_ 868 NEW_MSG_364: 8 XXX
 SG_ NEW_SIGNAL_5 : 21|1@0+ (1,0) [0|1] "" XXX
 SG_ NEW_SIGNAL_4 : 23|1@0+ (1,0) [0|1] "" XXX
 SG_ NEW_SIGNAL_2 : 26|2@0+ (1,0) [0|3] "" XXX
 SG_ NEW_SIGNAL_6 : 28|1@0+ (1,0) [0|1] "" XXX
 SG_ NEW_SIGNAL_3 : 31|2@0+ (1,0) [0|3] "" XXX
 SG_ NEW_SIGNAL_1 : 35|4@0+ (1,0) [0|15] "" XXX

BO_ 875 NEW_MSG_36B: 8 XXX
 SG_ NEW_SIGNAL_2 : 7|8@0+ (1,0) [0|255] "" XXX
 SG_ NEW_SIGNAL_1 : 23|8@0+ (1,0) [0|255] "" XXX

BO_ 883 NEW_MSG_373: 8 XXX
 SG_ NEW_SIGNAL_1 : 45|6@0+ (1,0) [0|63] "" XXX

BO_ 891 NEW_MSG_37B: 16 XXX
 SG_ NEW_SIGNAL_1 : 60|5@0+ (1,0) [0|31] "" XXX

BO_ 899 MAYBE_DRIVE_MODE: 8 XXX
 SG_ NEW_SIGNAL_1 : 18|3@0+ (1,0) [0|3] "" XXX

BO_ 1287 NEW_MSG_507: 8 XXX
 SG_ NEW_SIGNAL_1 : 63|8@0+ (1,0) [0|255] "" XXX

BO_ 1297 MAYBE_READY_1: 8 XXX
 SG_ NEW_SIGNAL_1 : 13|2@0+ (1,0) [0|3] "" XXX
 SG_ NEW_SIGNAL_2 : 16|1@0+ (1,0) [0|1] "" XXX

BO_ 1300 STEERING_WHEEL: 8 XXX
 SG_ STEERING_BUTTONS_LEFT_TOP : 12|1@0+ (1,0) [0|1] "" XXX
 SG_ STEERING_BUTTONS_LEFT_TOP_LONG : 13|1@0+ (1,0) [0|1] "" XXX
 SG_ STEERING_BUTTONS_LEFT_BOTTOM : 14|1@0+ (1,0) [0|1] "" XXX
 SG_ STEERING_BUTTONS_LEFT_BOTTOM_LONG : 15|1@0+ (1,0) [0|1] "" XXX
 SG_ STEERING_BUTTONS_LEFT_LEFT : 16|1@0+ (1,0) [0|1] "" XXX
 SG_ STEERING_BUTTONS_LEFT_LEFT_LONG : 17|1@0+ (1,0) [0|1] "" XXX
 SG_ STEERING_BUTTONS_LEFT_RIGHT : 18|1@0+ (1,0) [0|1] "" XXX
 SG_ STEERING_BUTTONS_LEFT_RIGHT_LONG : 19|1@0+ (1,0) [0|1] "" XXX
 SG_ STEERING_BUTTONS_LEFT_SCROLL_UP : 20|1@0+ (1,0) [0|1] "" XXX
 SG_ STEERING_BUTTONS_LEFT_SCROLL_DOWN : 24|1@0+ (1,0) [0|1] "" XXX
 SG_ STEERING_BUTTONS_LEFT_SCROLL_PRESS : 27|1@0+ (1,0) [0|1] "" XXX
 SG_ STEERING_BUTTONS_LEFT_SCROLL_PRESS_LONG : 28|1@0+ (1,0) [0|1] "" XXX
 SG_ STEERING_BUTTONS_RIGHT_TOP : 29|1@0+ (1,0) [0|1] "" XXX
 SG_ STEERING_BUTTONS_RIGHT_TOP_LONG : 30|1@0+ (1,0) [0|1] "" XXX
 SG_ STEERING_BUTTONS_RIGHT_BOTTOM : 32|1@0+ (1,0) [0|1] "" XXX
 SG_ STEERING_BUTTONS_RIGHT_BUTTOM_LONG : 33|1@0+ (1,0) [0|1] "" XXX
 SG_ STEERING_BUTTONS_RIGHT_LEFT : 34|1@0+ (1,0) [0|1] "" XXX
 SG_ STEERING_BUTTONS_RIGHT_LEFT_LONG : 35|1@0+ (1,0) [0|1] "" XXX
 SG_ STEERING_BUTTONS_RIGHT_RIGHT : 36|1@0+ (1,0) [0|1] "" XXX
 SG_ STEERING_BUTTONS_RIGHT_RIGHT_LONG : 37|1@0+ (1,0) [0|1] "" XXX
 SG_ STEERING_BUTTONS_RIGHT_SCROLL_UP : 40|1@0+ (1,0) [0|1] "" XXX
 SG_ STEERING_BUTTONS_RIGHT_SCROLL_DOWN : 43|1@0+ (1,0) [0|1] "" XXX
 SG_ STEERING_BUTTONS_RIGHT_SCROLL_PRESS : 46|1@0+ (1,0) [0|1] "" XXX
 SG_ STEERING_BUTTONS_RIGHT_SCROLL_PRESS_LONG : 47|1@0+ (1,0) [0|1] "" XXX

BO_ 1317 NEW_MSG_525: 8 XXX
 SG_ NEW_SIGNAL_3 : 19|12@0+ (1,0) [0|255] "" XXX
 SG_ NEW_SIGNAL_1 : 39|8@0+ (1,0) [0|255] "" XXX

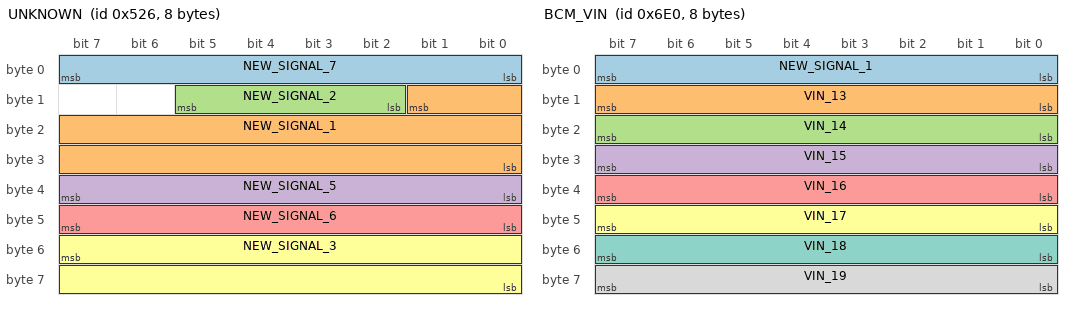
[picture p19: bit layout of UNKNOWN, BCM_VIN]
BO_ 1318 UNKNOWN: 8 XXX
 SG_ NEW_SIGNAL_7 : 7|8@0+ (1,0) [0|255] "" XXX
 SG_ NEW_SIGNAL_1 : 9|18@0+ (1,0) [0|255] "" XXX
 SG_ NEW_SIGNAL_2 : 13|4@0+ (1,0) [0|15] "" XXX
 SG_ NEW_SIGNAL_5 : 39|8@0+ (1,0) [0|255] "" XXX
 SG_ NEW_SIGNAL_6 : 47|8@0+ (1,0) [0|255] "" XXX
 SG_ NEW_SIGNAL_3 : 55|16@0+ (1,0) [0|255] "" XXX

BO_ 1329 NEW_MSG_531: 8 XXX
 SG_ NEW_SIGNAL_2 : 31|8@0+ (1,0) [0|255] "" XXX
 SG_ NEW_SIGNAL_1 : 39|7@0+ (1,0) [0|127] "" XXX
 SG_ MAYBE_MPH : 47|8@0+ (1,0) [0|255] "" XXX

BO_ 1410 NEW_MSG_582: 8 XXX
 SG_ NEW_SIGNAL_2 : 7|8@0+ (1,0) [0|255] "" XXX
 SG_ NEW_SIGNAL_1 : 63|8@0+ (1,0) [0|127] "" XXX

BO_ 1583 NEW_MSG_62F: 8 XXX
 SG_ NEW_SIGNAL_1 : 39|8@0+ (1,0) [0|255] "" XXX
 SG_ NEW_SIGNAL_2 : 63|8@0+ (1,0) [0|255] "" XXX

BO_ 1760 BCM_VIN: 8 XXX
 SG_ NEW_SIGNAL_1 : 7|8@0+ (1,0) [0|255] "" XXX
 SG_ VIN_13 : 15|8@0+ (1,0) [0|255] "" XXX
 SG_ VIN_14 : 23|8@0+ (1,0) [0|255] "" XXX
 SG_ VIN_15 : 31|8@0+ (1,0) [0|255] "" XXX
 SG_ VIN_16 : 39|8@0+ (1,0) [0|255] "" XXX
 SG_ VIN_17 : 47|8@0+ (1,0) [0|255] "" XXX
 SG_ VIN_18 : 55|8@0+ (1,0) [0|255] "" XXX
 SG_ VIN_19 : 63|8@0+ (1,0) [0|255] "" XXX

CM_ SG_ 524 MAYBE_LKAS_STATE "0 - Inactive, 1 - Ready, 2 - Lane markers missing?";
CM_ SG_ 790 CAMERA_DISPLAY_ID "1 - Front bumper, 2 - RL, 3 - RR, 4 - Rear bumper, 5 - Split b-pillar, 6 - Front bumper wide, 8 - Surround";
VAL_ 277 DIRECTION_1 1 "FORWARD" 2 "REVERSE" 3 "STOPPED";
VAL_ 277 DIRECTION_2 1 "FORWARD" 2 "REVERSE" 3 "STOPPED";
VAL_ 450 STEERING_TREND_DIRECTION 0 "LEFT" 1 "RIGHT";
VAL_ 528 TRAFFIC_LIGHT_COLOR 1 "RED" 2 "YELLOW" 3 "GREEN" 0 "NONE";
VAL_ 532 DRIVE_MODE_1 1 "PARK" 2 "NEUTRAL" 3 "REVERSE" 4 "DRIVE";
VAL_ 532 DRIVE_MODE_2 1 "PARK" 2 "NEUTRAL" 3 "REVERSE" 4 "DRIVE";
VAL_ 784 LEFT_STALK 0 "RESTING" 3 "HALF PRESS DOWN" 1 "FULL PRESS DOWN" 4 "HALF PRESS UP" 2 "FULL PRESS UP" 8 "PULL" 16 "PUSH";
VAL_ 784 LEFT_STALK_BUTTON 0 "RESTING" 1 "HALF PRESS" 2 "FULL PRESS";
VAL_ 821 HEADLIGHT_MODE 1 "OFF/DRL ONLY" 3 "AUTO" 7 "HEADLIGHTS ON" 5 "PARKING LIGHTS";
VAL_ 856 CRUISE_CONTROL_STATUS 0 "INACTIVE" 1 "SET" 2 "ACTIVE";
